# STM32L5x2 register map
File version: 1.3
Registers are 32-bit, read-write, reset 0x0 unless marked. A register's access mark holds for its fields unless they carry their own. Offsets are from the block's base; [hi:lo] are bit positions; {n}, {i} and the like mark numbered series.

## SPI1 — Serial peripheral interface
Base 0x40013000
Same registers: SPI2 0x40003800, SPI3 0x40003C00, SEC_SPI2 0x50003800, SEC_SPI3 0x50003C00, SEC_SPI1 0x50013000
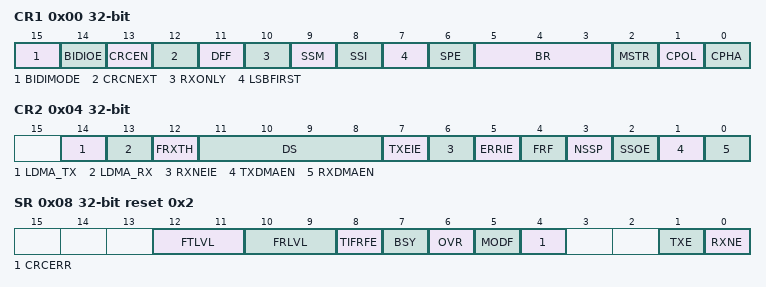
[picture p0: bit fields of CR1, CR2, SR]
0x00 CR1 — control register 1
  [15] BIDIMODE — Bidirectional data mode enable
  [14] BIDIOE — Output enable in bidirectional mode
  [13] CRCEN — Hardware CRC calculation enable
  [12] CRCNEXT — CRC transfer next
  [11] DFF — Data frame format
  [10] RXONLY — Receive only
  [9] SSM — Software slave management
  [8] SSI — Internal slave select
  [7] LSBFIRST — Frame format
  [6] SPE — SPI enable
  [5:3] BR — Baud rate control
  [2] MSTR — Master selection
  [1] CPOL — Clock polarity
  [0] CPHA — Clock phase
0x04 CR2 — control register 2
  [14] LDMA_TX — Last DMA transfer for transmission
  [13] LDMA_RX — Last DMA transfer for reception
  [12] FRXTH — FIFO reception threshold
  [11:8] DS — Data size
  [7] TXEIE — Tx buffer empty interrupt enable
  [6] RXNEIE — RX buffer not empty interrupt enable
  [5] ERRIE — Error interrupt enable
  [4] FRF — Frame format
  [3] NSSP — NSS pulse management
  [2] SSOE — SS output enable
  [1] TXDMAEN — Tx buffer DMA enable
  [0] RXDMAEN — Rx buffer DMA enable
0x08 SR access per field reset 0x2 — status register
  [12:11] FTLVL ro — FIFO transmission level
  [10:9] FRLVL ro — FIFO reception level
  [8] TIFRFE ro — TI frame format error
  [7] BSY ro — Busy flag
  [6] OVR ro — Overrun flag
  [5] MODF ro — Mode fault
  [4] CRCERR rw — CRC error flag
  [1] TXE ro — Transmit buffer empty
  [0] RXNE ro — Receive buffer not empty
0x0C DR — data register
  [15:0] DR — Data register
0x10 CRCPR reset 0x7 — CRC polynomial register
  [15:0] CRCPOLY
0x14 RXCRCR ro — RX CRC register
  [15:0] RxCRC
0x18 TXCRCR ro — TX CRC register
  [15:0] TxCRC

## TZIC
Base 0x40032800
Same registers: SEC_TZIC 0x50032800
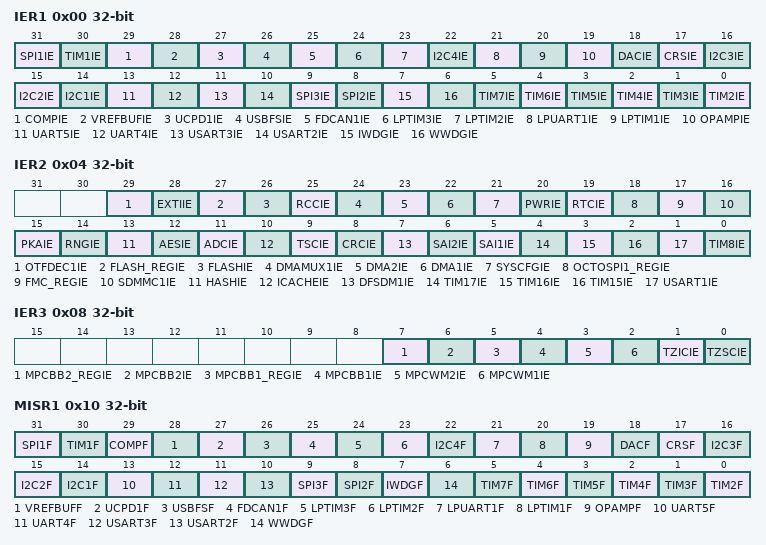
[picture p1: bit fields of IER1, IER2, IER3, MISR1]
0x00 IER1 — TZIC interrupt enable register 1
  [31] SPI1IE, [30] TIM1IE, [29] COMPIE, [28] VREFBUFIE, [27] UCPD1IE, [26] USBFSIE, [25] FDCAN1IE, [24] LPTIM3IE, [23] LPTIM2IE, [22] I2C4IE, [21] LPUART1IE, [20] LPTIM1IE, [19] OPAMPIE, [18] DACIE, [17] CRSIE, [16] I2C3IE, [15] I2C2IE, [14] I2C1IE, [13] UART5IE, [12] UART4IE, [11] USART3IE, [10] USART2IE, [9] SPI3IE, [8] SPI2IE, [7] IWDGIE, [6] WWDGIE, [n-2] TIM{n}IE (n=2..7)
0x04 IER2 — TZIC interrupt enable register 2
  [29] OTFDEC1IE, [28] EXTIIE, [27] FLASH_REGIE, [26] FLASHIE, [25] RCCIE, [24] DMAMUX1IE, [23] DMA2IE, [22] DMA1IE, [21] SYSCFGIE, [20] PWRIE, [19] RTCIE, [18] OCTOSPI1_REGIE, [17] FMC_REGIE, [16] SDMMC1IE, [15] PKAIE, [14] RNGIE, [13] HASHIE, [12] AESIE, [11] ADCIE, [10] ICACHEIE, [9] TSCIE, [8] CRCIE, [7] DFSDM1IE, [6] SAI2IE, [5] SAI1IE, [4] TIM17IE, [3] TIM16IE, [2] TIM15IE, [1] USART1IE, [0] TIM8IE
0x08 IER3 — TZIC interrupt enable register 3
  [7] MPCBB2_REGIE, [6] MPCBB2IE, [5] MPCBB1_REGIE, [4] MPCBB1IE, [3] MPCWM2IE, [2] MPCWM1IE, [1] TZICIE, [0] TZSCIE
0x10 MISR1 ro — TZIC interrupt status register 1
  [31] SPI1F, [30] TIM1F, [29] COMPF, [28] VREFBUFF, [27] UCPD1F, [26] USBFSF, [25] FDCAN1F, [24] LPTIM3F, [23] LPTIM2F, [22] I2C4F, [21] LPUART1F, [20] LPTIM1F, [19] OPAMPF, [18] DACF, [17] CRSF, [16] I2C3F, [15] I2C2F, [14] I2C1F, [13] UART5F, [12] UART4F, [11] USART3F, [10] USART2F, [9] SPI3F, [8] SPI2F, [7] IWDGF, [6] WWDGF, [n-2] TIM{n}F (n=2..7)
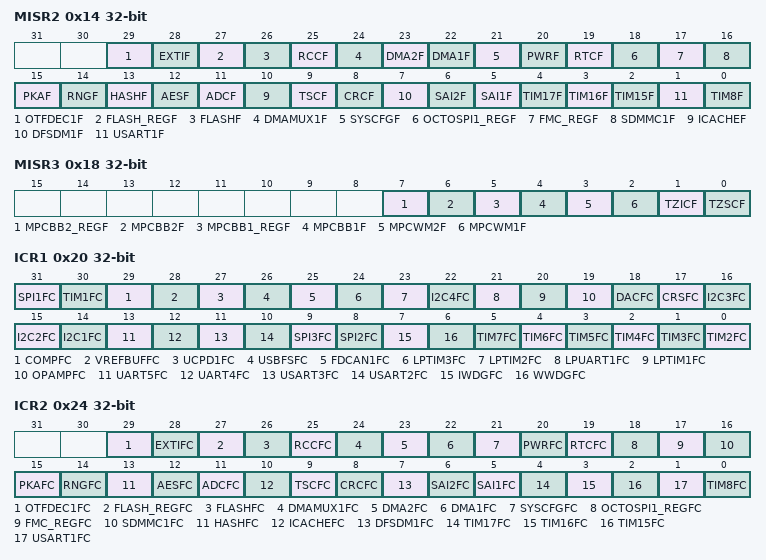
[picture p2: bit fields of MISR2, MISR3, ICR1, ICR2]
0x14 MISR2 — TZIC interrupt status register 2
  [29] OTFDEC1F, [28] EXTIF, [27] FLASH_REGF, [26] FLASHF, [25] RCCF, [24] DMAMUX1F, [23] DMA2F, [22] DMA1F, [21] SYSCFGF, [20] PWRF, [19] RTCF, [18] OCTOSPI1_REGF, [17] FMC_REGF, [16] SDMMC1F, [15] PKAF, [14] RNGF, [13] HASHF, [12] AESF, [11] ADCF, [10] ICACHEF, [9] TSCF, [8] CRCF, [7] DFSDM1F, [6] SAI2F, [5] SAI1F, [4] TIM17F, [3] TIM16F, [2] TIM15F, [1] USART1F, [0] TIM8F
0x18 MISR3 — TZIC interrupt status register 3
  [7] MPCBB2_REGF, [6] MPCBB2F, [5] MPCBB1_REGF, [4] MPCBB1F, [3] MPCWM2F, [2] MPCWM1F, [1] TZICF, [0] TZSCF
0x20 ICR1 wo — TZIC interrupt clear register 1
  [31] SPI1FC, [30] TIM1FC, [29] COMPFC, [28] VREFBUFFC, [27] UCPD1FC, [26] USBFSFC, [25] FDCAN1FC, [24] LPTIM3FC, [23] LPTIM2FC, [22] I2C4FC, [21] LPUART1FC, [20] LPTIM1FC, [19] OPAMPFC, [18] DACFC, [17] CRSFC, [16] I2C3FC, [15] I2C2FC, [14] I2C1FC, [13] UART5FC, [12] UART4FC, [11] USART3FC, [10] USART2FC, [9] SPI3FC, [8] SPI2FC, [7] IWDGFC, [6] WWDGFC, [n-2] TIM{n}FC (n=2..7)
0x24 ICR2 — TZIC interrupt clear register 2
  [29] OTFDEC1FC, [28] EXTIFC, [27] FLASH_REGFC, [26] FLASHFC, [25] RCCFC, [24] DMAMUX1FC, [23] DMA2FC, [22] DMA1FC, [21] SYSCFGFC, [20] PWRFC, [19] RTCFC, [18] OCTOSPI1_REGFC, [17] FMC_REGFC, [16] SDMMC1FC, [15] PKAFC, [14] RNGFC, [13] HASHFC, [12] AESFC, [11] ADCFC, [10] ICACHEFC, [9] TSCFC, [8] CRCFC, [7] DFSDM1FC, [6] SAI2FC, [5] SAI1FC, [4] TIM17FC, [3] TIM16FC, [2] TIM15FC, [1] USART1FC, [0] TIM8FC
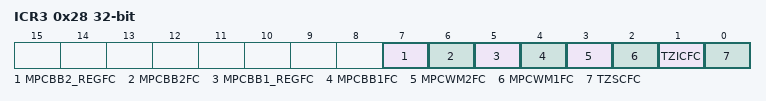
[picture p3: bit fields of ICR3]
0x28 ICR3 — TZIC interrupt clear register 3
  [7] MPCBB2_REGFC, [6] MPCBB2FC, [5] MPCBB1_REGFC, [4] MPCBB1FC, [3] MPCWM2FC, [2] MPCWM1FC, [1] TZICFC, [0] TZSCFC
